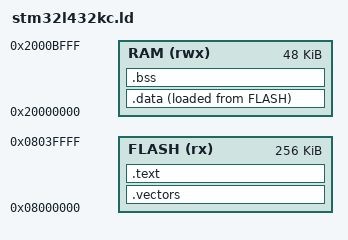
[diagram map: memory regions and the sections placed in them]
/*
 * Copyright (c) 2026 Clifford Swartz. MIT License (see LICENSE).
 */

ENTRY(reset_handler)

MEMORY
{
    FLASH (rx) : ORIGIN = 0x08000000, LENGTH = 256K
    RAM (rwx)  : ORIGIN = 0x20000000, LENGTH = 48K
}

SECTIONS
{
    .vectors : {
        KEEP(*(.vectors))
    } > FLASH

    .text : {
        *(.text*)
        *(.rodata*)
    } > FLASH

    .data : {
        *(.data*)
    } > RAM AT > FLASH

    .bss : {
        *(.bss*)
        *(COMMON)
    } > RAM
}
